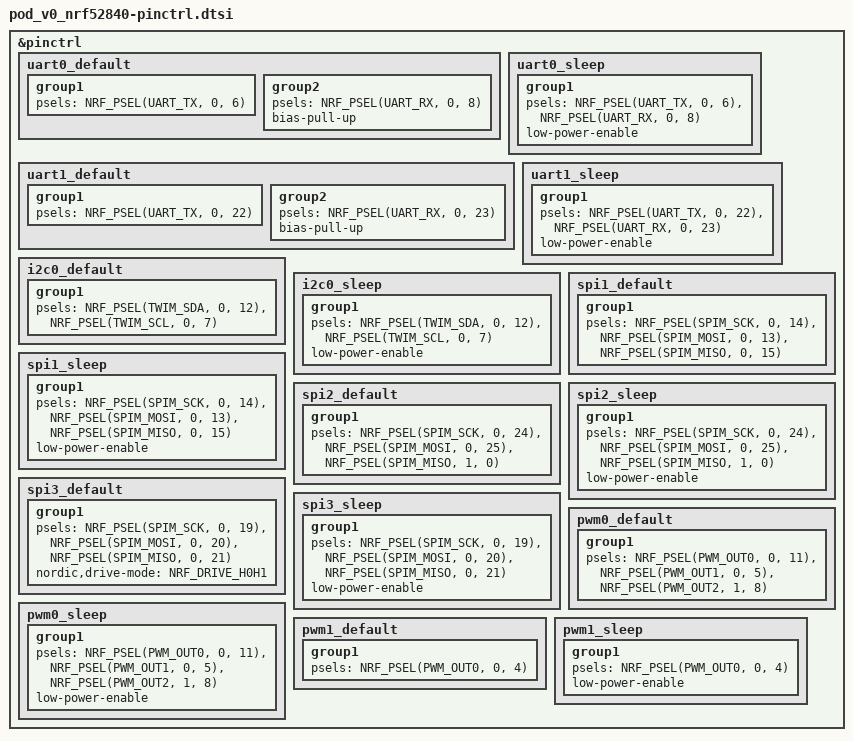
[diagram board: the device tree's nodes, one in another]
/*
 * Pin assignment of the pod v0, from the table "Asignación" of
 * docs/hardware/pod-v0.md (Raytac MDBT50Q-P1MV2 pads in the comments).
 */

&pinctrl {
	/* UARTE0: LC29H through the 3,4 V ↔ 2,8 V translator. */
	uart0_default: uart0_default {
		group1 {
			psels = <NRF_PSEL(UART_TX, 0, 6)>;	/* GNSS_TX, pad 22 */
		};
		group2 {
			psels = <NRF_PSEL(UART_RX, 0, 8)>;	/* GNSS_RX, pad 24 */
			/* The translator is high-Z with the GNSS off: internal pull-up. */
			bias-pull-up;
		};
	};

	uart0_sleep: uart0_sleep {
		group1 {
			psels = <NRF_PSEL(UART_TX, 0, 6)>,
				<NRF_PSEL(UART_RX, 0, 8)>;
			low-power-enable;
		};
	};

	/* UARTE1: backup console pad (the main console is RTT). */
	uart1_default: uart1_default {
		group1 {
			psels = <NRF_PSEL(UART_TX, 0, 22)>;	/* DBG_TX, pad 46 */
		};
		group2 {
			psels = <NRF_PSEL(UART_RX, 0, 23)>;	/* DBG_RX, pad 45 */
			bias-pull-up;
		};
	};

	uart1_sleep: uart1_sleep {
		group1 {
			psels = <NRF_PSEL(UART_TX, 0, 22)>,
				<NRF_PSEL(UART_RX, 0, 23)>;
			low-power-enable;
		};
	};

	/* TWIM0: BQ25180, MAX17048, BMP581 (DPS368 not mounted). 4,7 kΩ pull-ups on the board. */
	i2c0_default: i2c0_default {
		group1 {
			psels = <NRF_PSEL(TWIM_SDA, 0, 12)>,	/* I2C_SDA, pad 29 */
				<NRF_PSEL(TWIM_SCL, 0, 7)>;	/* I2C_SCL, pad 23 */
		};
	};

	i2c0_sleep: i2c0_sleep {
		group1 {
			psels = <NRF_PSEL(TWIM_SDA, 0, 12)>,
				<NRF_PSEL(TWIM_SCL, 0, 7)>;
			low-power-enable;
		};
	};

	/* SPIM1: sensor bus (LSM6DSV320X, DWM3000; ICM-42688-P and ADXL372 not mounted), 8 MHz. */
	spi1_default: spi1_default {
		group1 {
			psels = <NRF_PSEL(SPIM_SCK, 0, 14)>,	/* SENS_SCK, pad 36 */
				<NRF_PSEL(SPIM_MOSI, 0, 13)>,	/* SENS_MOSI, pad 37 */
				<NRF_PSEL(SPIM_MISO, 0, 15)>;	/* SENS_MISO, pad 39 */
		};
	};

	spi1_sleep: spi1_sleep {
		group1 {
			psels = <NRF_PSEL(SPIM_SCK, 0, 14)>,
				<NRF_PSEL(SPIM_MOSI, 0, 13)>,
				<NRF_PSEL(SPIM_MISO, 0, 15)>;
			low-power-enable;
		};
	};

	/* SPIM2: own bus of the E22-900M22S (SX1262), 8 MHz. */
	spi2_default: spi2_default {
		group1 {
			psels = <NRF_PSEL(SPIM_SCK, 0, 24)>,	/* LORA_SCK, pad 48 */
				<NRF_PSEL(SPIM_MOSI, 0, 25)>,	/* LORA_MOSI, pad 49 */
				<NRF_PSEL(SPIM_MISO, 1, 0)>;	/* LORA_MISO, pad 47 */
		};
	};

	spi2_sleep: spi2_sleep {
		group1 {
			psels = <NRF_PSEL(SPIM_SCK, 0, 24)>,
				<NRF_PSEL(SPIM_MOSI, 0, 25)>,
				<NRF_PSEL(SPIM_MISO, 1, 0)>;
			low-power-enable;
		};
	};

	/*
	 * SPIM3: own bus of the W25N NAND on the recommended QSPI pins, up to 32 MHz:
	 * high drive (H0H1) as the nRF52840 asks at 32 MHz (RXDELAY is set by the driver).
	 */
	spi3_default: spi3_default {
		group1 {
			psels = <NRF_PSEL(SPIM_SCK, 0, 19)>,	/* NAND_SCK, pad 42 */
				<NRF_PSEL(SPIM_MOSI, 0, 20)>,	/* NAND_MOSI, pad 44 */
				<NRF_PSEL(SPIM_MISO, 0, 21)>;	/* NAND_MISO, pad 43 */
			nordic,drive-mode = <NRF_DRIVE_H0H1>;
		};
	};

	spi3_sleep: spi3_sleep {
		group1 {
			psels = <NRF_PSEL(SPIM_SCK, 0, 19)>,
				<NRF_PSEL(SPIM_MOSI, 0, 20)>,
				<NRF_PSEL(SPIM_MISO, 0, 21)>;
			low-power-enable;
		};
	};

	/* PWM0: gates of the three NMOS of the RGB LED (100 kΩ pull-downs on the gates). */
	pwm0_default: pwm0_default {
		group1 {
			psels = <NRF_PSEL(PWM_OUT0, 0, 11)>,	/* LED_R, pad 27 */
				<NRF_PSEL(PWM_OUT1, 0, 5)>,	/* LED_G, pad 21 */
				<NRF_PSEL(PWM_OUT2, 1, 8)>;	/* LED_B, pad 25 */
		};
	};

	pwm0_sleep: pwm0_sleep {
		group1 {
			psels = <NRF_PSEL(PWM_OUT0, 0, 11)>,
				<NRF_PSEL(PWM_OUT1, 0, 5)>,
				<NRF_PSEL(PWM_OUT2, 1, 8)>;
			low-power-enable;
		};
	};

	/* PWM1: buzzer NMOS (not mounted). */
	pwm1_default: pwm1_default {
		group1 {
			psels = <NRF_PSEL(PWM_OUT0, 0, 4)>;	/* BUZZER, pad 20 */
		};
	};

	pwm1_sleep: pwm1_sleep {
		group1 {
			psels = <NRF_PSEL(PWM_OUT0, 0, 4)>;
			low-power-enable;
		};
	};
};
